# MEC1322 register map
Vendor: Microchip Technology Inc.; Series: ARMCM4F; File version: 1.0
CPU: CM4 r1p0, little endian, MPU, FPU, 3 interrupt priority bits
Registers are 32-bit, read-write, reset 0x0 unless marked. A register's access mark holds for its fields unless they carry their own. Offsets are from the block's base; [hi:lo] are bit positions.

## SMB0 — The SMBus interface can handle standard SMBus 2.0 protocols as well as I2C interface.
Base 0x40001800
Same registers: SMB1 0x4000AC00, SMB2 0x4000B000, SMB3 0x4000B400
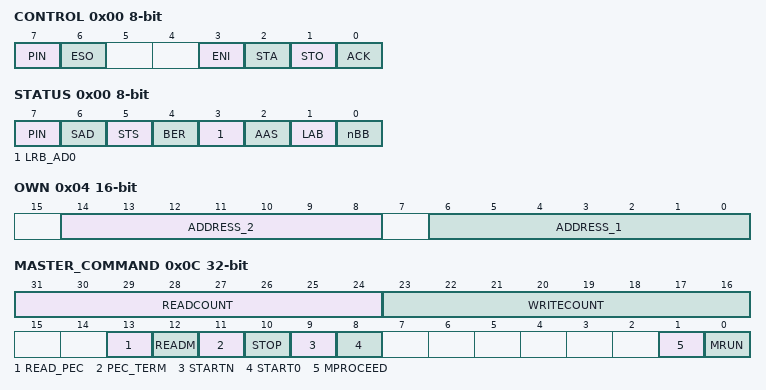
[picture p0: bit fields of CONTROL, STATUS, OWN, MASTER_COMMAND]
0x00 CONTROL 8-bit write
  [7] PIN rw — The Pending Interrupt Not (PIN) bit serves as a software reset function. Writing the PIN bit to a logic '1' de-asserts all status bits except for the nBB bit which is not affected by the PIN bit. The PIN bit is a self-clearing bit. Writing this bit to a logic '0' has no effect.
  [6] ESO rw — The Enable Serial Output bit (ESO) enables and disables the SMB Controller Core serial data output (SDAT)
  [3] ENI rw — Enable Interrupt bit (ENI) controls the Interrupt Interface
  [2] STA rw — The STA and STO bits control the generation of the I2C Start condition and the transmission of the Slave Address and R/nW bit (from the Data Register), generation of repeated Start condition, and generation of the Stop condition
  [1] STO rw — See STA description
  [0] ACK rw — The Acknowledge bit (ACK) must normally be asserted ('1'). This causes the controller to send an acknowledge automatically after each byte (this occurs during the 9th clock pulse). The ACK bit must not be asserted ('0') when the controller is operating in master/receiver mode and requires no further data to be sent from the slave transmitter. This causes a negative acknowledge on the I2C bus, which halts further transmission from the slave device.
0x00 STATUS 8-bit read
  [7] PIN ro — Pending Interrupt bit
  [6] SAD ro — SMBus Address Decoded (SAD)
  [5] STS ro — When in slave receiver mode, STS is asserted ('1') when an externally generated STOP condition is detected. Note that STS is used only in slave receiver mode.
  [4] BER ro — When Bus Error (BER) is asserted, a misplaced START or STOP condition or Bus Time-Outs have been detected.
  [3] LRB_AD0 ro — The "Last Received Bit" or "Address 0" (general call) bit (LRB/AD0) serves a dual function and is valid only while the PIN bit is asserted ('0'). When the AAS bit is not asserted ('0') (i.e., not addressed as a slave), the LRB/AD0 holds the value of the last received bit over the bus. When the AAS bit is asserted ('1') (i.e., addressed as slave), the SMB Controller Core has been addressed as a slave.
  [2] AAS ro — The Addressed As Slave bit (AAS) is valid only when PIN is asserted ('0'). When acting as slave, AAS is set when an incoming address over the bus matches the value in the Own Address Register or if the 'general call' address (00h) has been received
  [1] LAB ro — The Lost Arbitration Bit (LAB) is set when, in multi-master operation, arbitration is lost to another master on the bus
  [0] nBB ro — The Bus Busy bit (nBB) is a read-only flag indicating when the bus is in use. A zero indicates that the bus is busy and access is not possible.
0x04 OWN 16-bit — Own Address Register. Note that the Data Register and Own Address fields are offset by one bit, so that programming Own Address 1 with a value of 55h will result in the value AAh being recognized as the SMB Controller Core slave address.
  [14:8] ADDRESS_2 — The Own Address 2 bits configure one of the two addresses to which the SMB Controller Core will respond when addressed as a slave.
  [6:0] ADDRESS_1 — The Own Address 1 bits configure one of the two addresses to which the SMB Controller Core will respond when addressed as a slave.
0x08 DATA 8-bit
0x0C MASTER_COMMAND — SMBus Master Command Register
  [31:24] READCOUNT — This field is a count of the number of bytes to read in from the SMBus to the SMBus Master Receive Buffer Register and must be greater than 0 in order for the Master State Machine to initiate a read phase. It is decremented by 1 for each byte read from the SMBus into the SMBus Master Receive Buffer Register. It can be overwritten by the first byte read in from the SMBus.
  [23:16] WRITECOUNT — This field is a count of the number of bytes to transmit to the SMBus from the SMBus Master Transmit Buffer Register It is decremented by 1 for each byte written to the SMBus from the SMBus Master Transmit Buffer Register.
  [13] READ_PEC — If this bit is 0, reading from the SMBus stops when ReadCount reaches 0. If this bit is 1, reading continues when ReadCount is 0 for one more byte.
  [12] READM — If this bit is 1, then the ReadCount field is replaced by the byte that is read from the SMBus when ReadCount[7:0] is 1. After ReadCount[7:0] is updated, this bit is cleared to 0.
  [11] PEC_TERM — If this bit is 1, a copy of the PEC register is transmitted when WriteCount is 0. After the PEC register is read, both the PEC register and this bit are cleared to 0.
  [10] STOP — If this bit is 1, send a Stop bit after the transaction completes.
  [9] STARTN — If this bit is 1, send a Start bit just before the last byte of the WriteCount is sent to the SMBus transmitter.
  [8] START0 — If this bit is 1, send a Start bit on the SMBus before the first byte of the WriteCount is sent to the SMBus transmitter.
  [1] MPROCEED — When this bit is 0, the Master State Machine does not transition out of the IDLE or PAUSE states. When this bit is 1, the Master State Machine immediately transitions to the WAIT-BUSBUSY and MRUN-RECEIVE states, respectively.
  [0] MRUN — While this bit is 1, transfer bytes over SMBus. As long as WriteCount is non-zero, a byte from the Master Transmit Buffer is transmitted to the slave device and WriteCount is decremented.
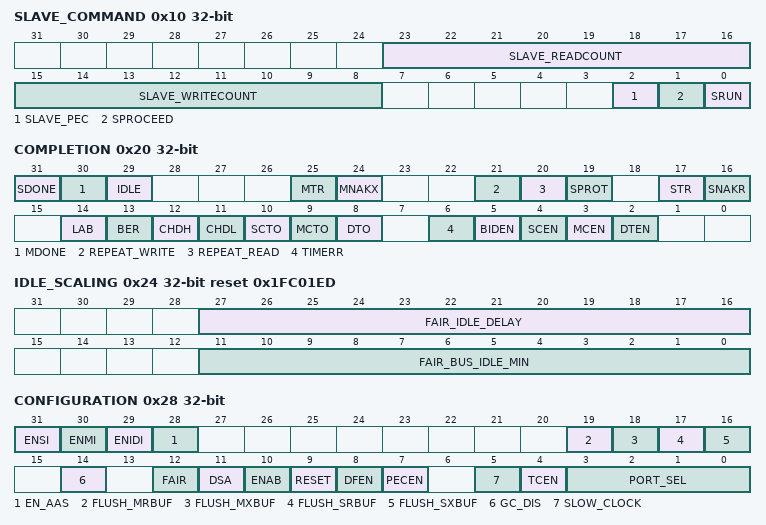
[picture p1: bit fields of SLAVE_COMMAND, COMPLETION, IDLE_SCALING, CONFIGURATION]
0x10 SLAVE_COMMAND — SMBus Slave Command Register
  [23:16] SLAVE_READCOUNT — This field is decremented each time a byte is copied from DATA to the SMBus Slave Receive Buffer Register.
  [15:8] SLAVE_WRITECOUNT — This field is set to the number of bytes software expects to send to the Master.
  [2] SLAVE_PEC — If Slave_WriteCount is 0 and Slave_PEC is 1 when the Master requests data, the PEC Register is copied to the DATA register. After the PEC Register is copied to the SMBus, the PEC Register is cleared and Slave_PEC is set to 0.
  [1] SPROCEED — When this bit is 0, the Slave State Machine does not transition out of the IDLE, REPEAT_START_WRITE or REPEAT_START_READ states. When this bit is 1, the Slave State Machine immediately transitions to the START_WAIT, RECEIVE and TRANSMIT states, respectively.
  [0] SRUN — Setting this bit to 1 enables the Slave State Machine to operate.
0x14 PEC 8-bit — PEC byte
0x18 DATA_TIMING2 8-bit — HOLD TIME START BIT This is the value of the timing requirement tHd:Sta in the I2C specification. This is used to hold the clock until the Hold Time for the Start Bit has been satisfied
0x20 COMPLETION
  [31] SDONE — If this bit is 1, Slave State machine completed operation and returned to the Idle state. It is cleared when written with a 1. Writes of a 0 have no effect.(R/WC)
  [30] MDONE — If this bit is 1, Master State machine completed operation and returned to the Idle state. It is cleared when written with a 1. Writes of a 0 have no effect. (R/WC)
  [29] IDLE — This bit is set when the I2C bus becomes idle (on the rising edge of nBB). (R/WC)
  [25] MTR ro — 0: Master has just finished the receive phase of a transaction. 1: Master has just finished the transmit phase of a transaction.
  [24] MNAKX — If this bit is 1, the Master state machine received a NACK from the receiving Slave while the Master was transmitting data over the SMBus interface. (R/WC)
  [21] REPEAT_WRITE — If this bit is 1, the Slave State Machine stopped because it detected a Repeat Start bit, with bit[0] of the byte containing the slave address equal to 0, indicating that the Master requested a Write operation.
  [20] REPEAT_READ — If this bit is 1, the Slave State Machine stopped because it detected a Repeat Start bit, with bit[0] of the byte containing the slave address equal to 1, indicating that the Master requested a Read operation.
  [19] SPROT — If this bit is 1, the WriteCount[7:0] counter in the Slave state machine either counted down to 0 before the Master sent a NACK signal, or the Slave received a NACK signal before the counter reached 0.
  [17] STR ro — 0: Slave has just finished the receive phase of a transaction. 1: Slave has just finished the transmit phase of a transaction.
  [16] SNAKR — If this bit is 1, the Slave state machine sent a NACK to the transmitting Master while the Slave was receiving data from the SMBus interface.
  [14] LAB — If this bit is 1, the LAB bit in the Status register was set while either the Slave state machine or the Master state machine was not in the Idle state.(R/WC)
  [13] BER — If this bit is 1, the BER bit in the Status register was set while either the Slave state machine or the Master state machine was not in the Idle state.(R/WC)
  [12] CHDH — CHDH is the bus idle time-out detect bit(R/WC)
  [11] CHDL — CHDL is the clock high time-out detect bit(R/WC)
  [10] SCTO — SCTO is the Slave Cumulative Time-out bit(R/WC)
  [9] MCTO — MCTO is the Master Cumulative Time-out bit. (R/WC)
  [8] DTO — DTO is the Device Time-out bit. (R/WC)
  [6] TIMERR ro — The Time-out Error Detected bit (TIMERR) is asserted ('1') whenever any of the enabled time-out error detect status bits (CHDH, CHDL, SCTO, MCTO and DTO) are asserted.
  [5] BIDEN — When BIDEN is asserted ('1'), Bus Idle Detect Time-Out checking is enabled. When BIDEN is not asserted ('0'), Bus Idle Detect Time-Out checking is disabled.
  [4] SCEN — When SCEN is asserted ('1'), Slave Cumulative Time-Out checking is enabled. When SCEN is not asserted ('0'), Slave Cumulative Time-Out checking is disabled.
  [3] MCEN — When MCEN is asserted ('1'), Master Cumulative Time-Out checking is enabled. When MCEN is not asserted ('0'), Master Cumulative Time-Out checking is disabled.
  [2] DTEN — When DTEN is asserted ('1'), Device Time-out checking is enabled. When DTEN is not asserted ('0'), Device Time-out checking is disabled.
0x24 IDLE_SCALING reset 0x1FC01ED
  [27:16] FAIR_IDLE_DELAY — This field defines the number of ticks of the baud clock required to program the delay. The default value for this field sets the delay period to 32us, which is the appropriate value for a 100 KHz bus
  [11:0] FAIR_BUS_IDLE_MIN — This field defines the number of ticks of the baud clock required to satisfy the fairness protocol. The default value for this field sets the idle window to 31us, which is the appropriate value for a 100 KHz bus
0x28 CONFIGURATION
  [31] ENSI — If this bit is 1, the Slave Done interrupt is enabled. If this bit is 0, the Slave Done interrupt is disabled
  [30] ENMI — If this bit is 1, the Master Done interrupt is enabled. If this bit is 0, the Master Done interrupt is disabled.
  [29] ENIDI — If this bit is 1, the Idle interrupt is enabled. If this bit is 0, the Idle interrupt is disabled.
  [28] EN_AAS ro — 0: Disable the AAS Interrupt, 1: Enable the AAS Interrupt
  [19] FLUSH_MRBUF write — A write of a 1 to this bit forces the SMBus Master Receive Buffer Register to be marked empty. A write of 0 has no effect. This is a self-clearing bit.
  [18] FLUSH_MXBUF write — A write of a 1 to this bit forces the SMBus Master Transmit Buffer Register to be marked empty. A write of 0 has no effect. This is a self-clearing bit.
  [17] FLUSH_SRBUF write — A write of a 1 to this bit forces the SMBus Slave Receive Buffer Register to be marked empty. A write of 0 has no effect. This is a self-clearing bit.
  [16] FLUSH_SXBUF write — A write of a 1 to this bit forces the SMBus Slave Transmit Buffer Register to be marked empty. A write of 0 has no effect. This is a self-clearing bit.
  [14] GC_DIS ro — This is the General Call Disable bit. 0: the response to the General Call address as a slave is enabled. 1: the response to the General Call address as a slave is disabled.
  [12] FAIR — If this bit is 1, the MCTP Fairness protocol is in effect.
  [11] DSA — 0: Slave Address I2C Compatibility Mode (default). 1: SMBus Address Decode Mode
  [10] ENAB — When ENAB (Enable) is not asserted ('0') (default), the SMB Controller Core is disabled and in the lowest power consumption state (Disabled State). The ENAB bit must be asserted ('1') for normal operation.
  [9] RESET — When RESET is asserted ('1'), all logic and registers except for the RESET bit itself are initialized to the power-on default state.
  [8] DFEN — When the Digital Filter Enable bit (DFEN) is asserted ('1'), the Digital Filter is enabled. When DFEN is not asserted ('0') (default), the Digital Filter is bypassed.
  [7] PECEN — When the PEC Enable bit (PECEN) is asserted ('1'), Hardware PEC Support is enabled
  [5] SLOW_CLOCK ro — When this bit is 1, the base period for the Bus Clock Register is multiplied by 4, and thus the frequency is divided by 4.
  [4] TCEN — When the Timing Check Enable bit (TCEN) is asserted ('1'), Bus Time-Outs are enabled
  [3:0] PORT_SEL — The PORT SEL [3:0] bits determine which one of 16 possible bus ports apply to the active 2-wire SDAT and SCLK bus pair.
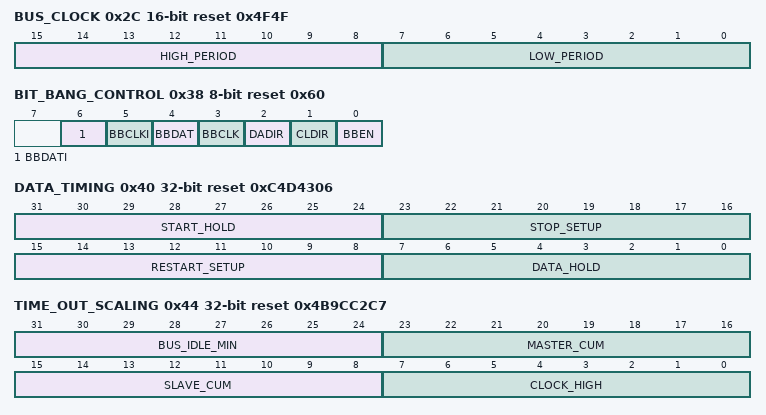
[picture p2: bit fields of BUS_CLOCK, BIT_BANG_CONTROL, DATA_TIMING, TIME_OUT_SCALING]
0x2C BUS_CLOCK 16-bit reset 0x4F4F
  [15:8] HIGH_PERIOD — This field defines the number of I2C Baud Clock periods that make up the high phase of the I2C/SMBus bus clock.
  [7:0] LOW_PERIOD — This field defines the number of I2C Baud Clock periods that make up the low phase of the I2C/SMBus bus clock.
0x30 BLOCK_ID 8-bit ro
0x34 REVISION 8-bit ro
0x38 BIT_BANG_CONTROL 8-bit reset 0x60
  [6] BBDATI ro — Bit-Bang Data In. The BBDATI bit always returns the state of SDAT
  [5] BBCLKI ro — Bit-Bang Clock In. The BBCLKI bit always returns the state of SCLK.
  [4] BBDAT — Bit-Bang Data. The BBDAT bit controls the state of SDAT when BBEN = and DADIR = '1'
  [3] BBCLK — Bit-Bang Clock. The BBCLK bit controls the state of SCLK when BBEN = and CLDIR = '1'
  [2] DADIR — Bit-Bang Data Direction. The DADIR bit controls the direction of SDAT. 0 - Input. 1 - Output
  [1] CLDIR — Bit-Bang Clock Direction. The CLDIR bit controls the direction of SCLK. 0 - Input, 1 - Output
  [0] BBEN — Bit-Bang Mode Enable. 0 - Bit Bang Mode Disabled. 1 - Bit Bang Mode Enabled
0x40 DATA_TIMING reset 0xC4D4306
  [31:24] START_HOLD — The Start Hold [7:0] timer determines the SCLK hold time following SDAT driven low during a START condition.
  [23:16] STOP_SETUP — The Stop Setup [7:0] timer determines the SDAT setup time from the rising edge of SCLK for a STOP condition.
  [15:8] RESTART_SETUP — The Restart Setup [7:0] timer determines the SDAT setup time from the rising edge of SCLK for a repeated START condition.
  [7:0] DATA_HOLD — The Data Hold [7:0] timer determines the SDAT hold time following SCLK driven low.
0x44 TIME_OUT_SCALING reset 0x4B9CC2C7
  [31:24] BUS_IDLE_MIN — Bus Idle Minimum time = Bus Idle Min [7:0] x Baud_Clock_Period
  [23:16] MASTER_CUM — Master Cumulative Time-Out duration = Master Cum Time-Out [7:0] x Baud_Clock_Periodx 512
  [15:8] SLAVE_CUM — Slave Cumulative Time-Out duration = Slave Cum Time-Out [7:0] x Baud_Clock_Period x 1024
  [7:0] CLOCK_HIGH — Clock High time out period = Clock High Time-Out [7:0] x Baud_Clock_Period x 2
0x48 SLAVE_TRANSMIT_BUFFER 8-bit — SMBus Slave Transmit Buffer Register
0x4C SLAVE_RECEIVE_BUFFER 8-bit — SMBus Slave Receive Buffer Register
0x50 MASTER_TRANSMIT_BUFER 8-bit — SMBus Master Transmit Bufer Register
0x54 MASTER_RECEIVE_BUFFER 8-bit — SMBus Master Receive Buffer Register
